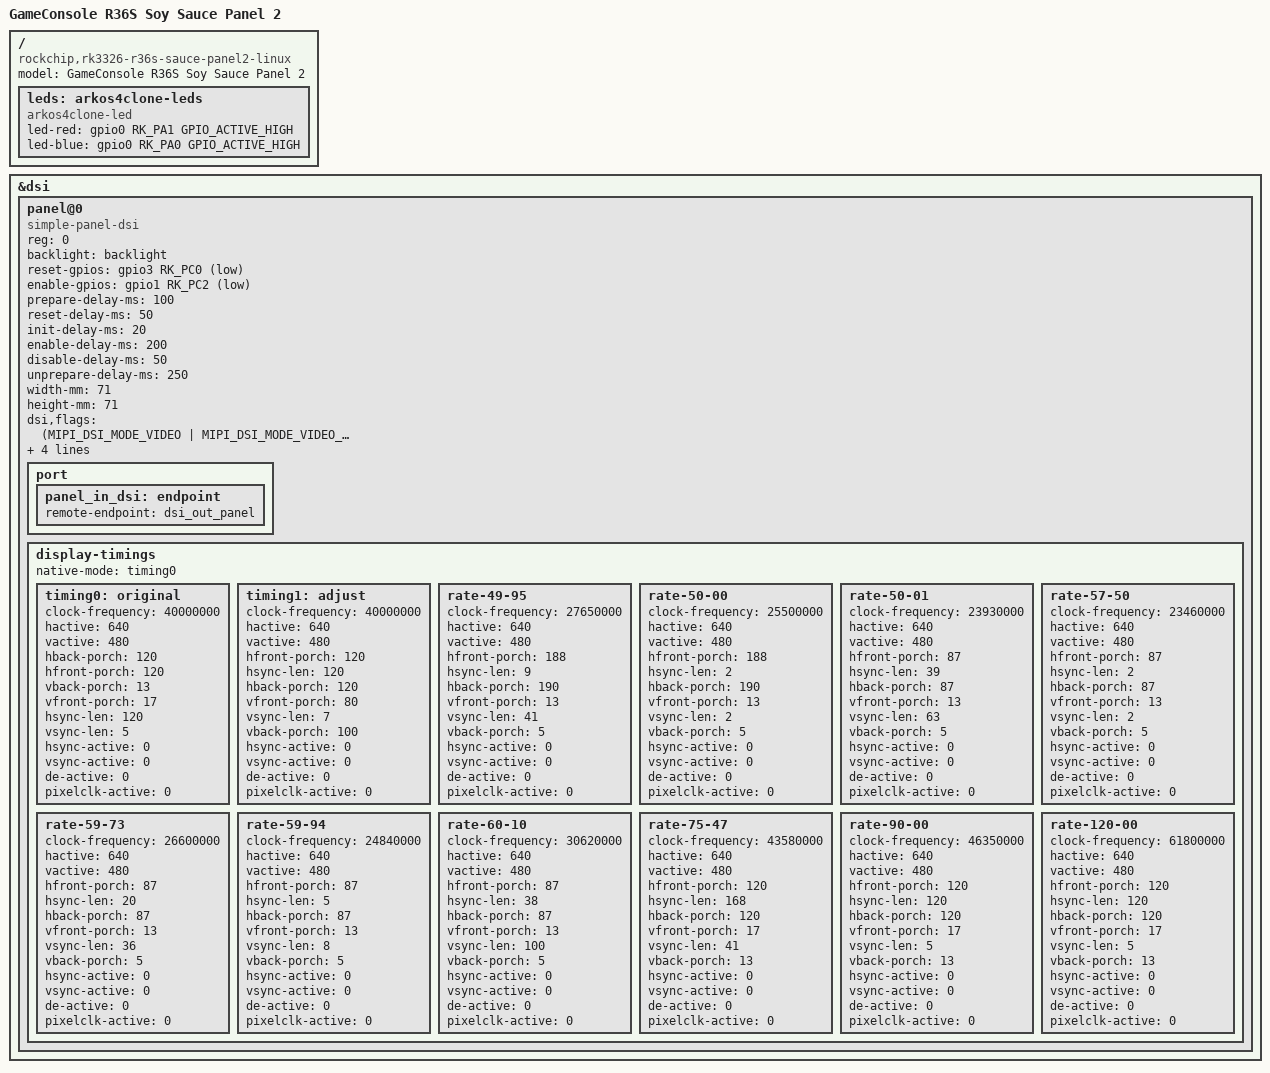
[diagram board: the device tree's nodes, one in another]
// SPDX-License-Identifier: (GPL-2.0+ OR MIT)
/*
* Copyright (c) 2026 kk&lcdyk
*
* R36S 酱油 Panel 2
*
*/

/dts-v1/;
#include "rk3326-r36s-sauce.dtsi"

/ {
	model = "GameConsole R36S Soy Sauce Panel 2";
	compatible = "rockchip,rk3326-r36s-sauce-panel2-linux", "rockchip,rk3326";

	leds: arkos4clone-leds {
		compatible = "arkos4clone-led";

		led-red = <&gpio0 RK_PA1 GPIO_ACTIVE_HIGH>;
		led-blue = <&gpio0 RK_PA0 GPIO_ACTIVE_HIGH>;
	};
};

&dsi {
	status = "okay";

	panel@0 {
		compatible = "simple-panel-dsi";
		reg = <0>;
		/* pwm1 backlight */
		backlight = <&backlight>;
		/* LCD reset gpio GPIO3.B7 */
		reset-gpios = <&gpio3 RK_PC0 GPIO_ACTIVE_LOW>;
		/* power-supply-gpio GPIO0.B5  */
		enable-gpios = <&gpio1 RK_PC2 GPIO_ACTIVE_LOW>;
		prepare-delay-ms = <100>;
		reset-delay-ms = <50>;
		init-delay-ms = <20>;
		enable-delay-ms = <200>;
		disable-delay-ms = <50>;
		unprepare-delay-ms = <250>;
		width-mm = <71>;
		height-mm = <71>;
		dsi,flags  = <(MIPI_DSI_MODE_VIDEO |
		MIPI_DSI_MODE_VIDEO_BURST |
		MIPI_DSI_MODE_LPM |
		MIPI_DSI_MODE_EOT_PACKET)>;
		dsi,format = <MIPI_DSI_FMT_RGB888>;
		dsi,lanes = <4>;
		panel-init-sequence = [05 96 01 11 05 32 01 29];
		panel-exit-sequence = [05 14 01 28 05 0a 01 10];

		port {
			panel_in_dsi: endpoint {
				remote-endpoint = <&dsi_out_panel>;
			};
		};

		display-timings {
			native-mode = <&timing0>;

			// 40.00MHz / (640+120+120+120)×(480+17+5+13) = 1000×515 = 77.67 Hz
			timing0: original {
				clock-frequency = <40000000>;
				hactive = <640>;
				vactive = <480>;
				hback-porch = <120>;
				hfront-porch = <120>;
				vback-porch = <13>;
				vfront-porch = <17>;
				hsync-len = <120>;
				vsync-len = <5>;
				hsync-active = <0>;
				vsync-active = <0>;
				de-active = <0>;
				pixelclk-active = <0>;
			};

			// 40.00MHz / (640+120+120+120)×(480+80+7+100) = 1000×667 = 59.97 Hz
			timing1: adjust {
				clock-frequency = <40000000>;
				hactive = <640>;
				vactive = <480>;
				hfront-porch = <120>;
				hsync-len = <120>;
				hback-porch = <120>;
				vfront-porch = <80>;
				vsync-len = <7>;
				vback-porch = <100>;
				hsync-active = <0>;
				vsync-active = <0>;
				de-active = <0>;
				pixelclk-active = <0>;
			};

			// 27.65MHz / (640+188+9+190)×(480+13+41+5) = 1027×539 = 49.95 Hz
			rate-49-95 {
				clock-frequency = <27650000>;
				hactive = <640>;
				vactive = <480>;
				hfront-porch = <188>;
				hsync-len = <9>;
				hback-porch = <190>;
				vfront-porch = <13>;
				vsync-len = <41>;
				vback-porch = <5>;
				hsync-active = <0>;
				vsync-active = <0>;
				de-active = <0>;
				pixelclk-active = <0>;
			};

			// 25.50MHz / (640+188+2+190)×(480+13+2+5) = 1020×500 = 50.00 Hz
			rate-50-00 {
				clock-frequency = <25500000>;
				hactive = <640>;
				vactive = <480>;
				hfront-porch = <188>;
				hsync-len = <2>;
				hback-porch = <190>;
				vfront-porch = <13>;
				vsync-len = <2>;
				vback-porch = <5>;
				hsync-active = <0>;
				vsync-active = <0>;
				de-active = <0>;
				pixelclk-active = <0>;
			};

			// 23.93MHz / (640+87+39+87)×(480+13+63+5) = 853×561 = 50.01 Hz
			rate-50-01 {
				clock-frequency = <23930000>;
				hactive = <640>;
				vactive = <480>;
				hfront-porch = <87>;
				hsync-len = <39>;
				hback-porch = <87>;
				vfront-porch = <13>;
				vsync-len = <63>;
				vback-porch = <5>;
				hsync-active = <0>;
				vsync-active = <0>;
				de-active = <0>;
				pixelclk-active = <0>;
			};

			// 23.46MHz / (640+87+2+87)×(480+13+2+5) = 816×500 = 57.50 Hz
			rate-57-50 {
				clock-frequency = <23460000>;
				hactive = <640>;
				vactive = <480>;
				hfront-porch = <87>;
				hsync-len = <2>;
				hback-porch = <87>;
				vfront-porch = <13>;
				vsync-len = <2>;
				vback-porch = <5>;
				hsync-active = <0>;
				vsync-active = <0>;
				de-active = <0>;
				pixelclk-active = <0>;
			};

			// 26.60MHz / (640+87+20+87)×(480+13+36+5) = 834×534 = 59.73 Hz
			rate-59-73 {
				clock-frequency = <26600000>;
				hactive = <640>;
				vactive = <480>;
				hfront-porch = <87>;
				hsync-len = <20>;
				hback-porch = <87>;
				vfront-porch = <13>;
				vsync-len = <36>;
				vback-porch = <5>;
				hsync-active = <0>;
				vsync-active = <0>;
				de-active = <0>;
				pixelclk-active = <0>;
			};

			// 24.84MHz / (640+87+5+87)×(480+13+8+5) = 819×506 = 59.94 Hz
			rate-59-94 {
				clock-frequency = <24840000>;
				hactive = <640>;
				vactive = <480>;
				hfront-porch = <87>;
				hsync-len = <5>;
				hback-porch = <87>;
				vfront-porch = <13>;
				vsync-len = <8>;
				vback-porch = <5>;
				hsync-active = <0>;
				vsync-active = <0>;
				de-active = <0>;
				pixelclk-active = <0>;
			};

			// 30.62MHz / (640+87+38+87)×(480+13+100+5) = 852×598 = 60.10 Hz
			rate-60-10 {
				clock-frequency = <30620000>;
				hactive = <640>;
				vactive = <480>;
				hfront-porch = <87>;
				hsync-len = <38>;
				hback-porch = <87>;
				vfront-porch = <13>;
				vsync-len = <100>;
				vback-porch = <5>;
				hsync-active = <0>;
				vsync-active = <0>;
				de-active = <0>;
				pixelclk-active = <0>;
			};

			// 43.58MHz / (640+120+168+120)×(480+17+41+13) = 1048×551 = 75.47 Hz
			rate-75-47 {
				clock-frequency = <43580000>;
				hactive = <640>;
				vactive = <480>;
				hfront-porch = <120>;
				hsync-len = <168>;
				hback-porch = <120>;
				vfront-porch = <17>;
				vsync-len = <41>;
				vback-porch = <13>;
				hsync-active = <0>;
				vsync-active = <0>;
				de-active = <0>;
				pixelclk-active = <0>;
			};

			// 46.35MHz / (640+120+120+120)×(480+17+5+13) = 1000×515 = 90.00 Hz
			rate-90-00 {
				clock-frequency = <46350000>;
				hactive = <640>;
				vactive = <480>;
				hfront-porch = <120>;
				hsync-len = <120>;
				hback-porch = <120>;
				vfront-porch = <17>;
				vsync-len = <5>;
				vback-porch = <13>;
				hsync-active = <0>;
				vsync-active = <0>;
				de-active = <0>;
				pixelclk-active = <0>;
			};

			// 61.80MHz / (640+120+120+120)×(480+17+5+13) = 1000×515 = 120.00 Hz
			rate-120-00 {
				clock-frequency = <61800000>;
				hactive = <640>;
				vactive = <480>;
				hfront-porch = <120>;
				hsync-len = <120>;
				hback-porch = <120>;
				vfront-porch = <17>;
				vsync-len = <5>;
				vback-porch = <13>;
				hsync-active = <0>;
				vsync-active = <0>;
				de-active = <0>;
				pixelclk-active = <0>;
			};
		};
	};
};
